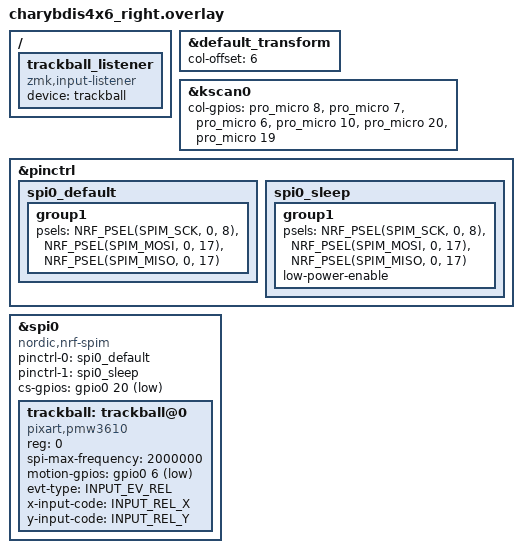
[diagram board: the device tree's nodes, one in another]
#include "charybdis4x6.dtsi"
/* 아래 줄 추가: 마우스 입력 코드를 쓰기 위한 필수 헤더 */
#include <dt-bindings/zmk/input_transform.h>

&default_transform {
    col-offset = <6>;
};

&kscan0 {
    /* 핀맵 유지 */
    col-gpios
        = <&pro_micro 8 (GPIO_ACTIVE_HIGH | GPIO_PULL_DOWN)>
        , <&pro_micro 7 (GPIO_ACTIVE_HIGH | GPIO_PULL_DOWN)>
        , <&pro_micro 6 (GPIO_ACTIVE_HIGH | GPIO_PULL_DOWN)>
        , <&pro_micro 10 (GPIO_ACTIVE_HIGH | GPIO_PULL_DOWN)>
        , <&pro_micro 20 (GPIO_ACTIVE_HIGH | GPIO_PULL_DOWN)>
        , <&pro_micro 19 (GPIO_ACTIVE_HIGH | GPIO_PULL_DOWN)>
        ;
};

&pinctrl {
    spi0_default: spi0_default {
        group1 {
            psels = <NRF_PSEL(SPIM_SCK, 0, 8)>,
                <NRF_PSEL(SPIM_MOSI, 0, 17)>,
                <NRF_PSEL(SPIM_MISO, 0, 17)>;
        };
    };

    spi0_sleep: spi0_sleep {
        group1 {
            psels = <NRF_PSEL(SPIM_SCK, 0, 8)>,
                <NRF_PSEL(SPIM_MOSI, 0, 17)>,
                <NRF_PSEL(SPIM_MISO, 0, 17)>;
            low-power-enable;
        };
    };
};

&spi0 {
    status = "okay";
    compatible = "nordic,nrf-spim";
    pinctrl-0 = <&spi0_default>;
    pinctrl-1 = <&spi0_sleep>;
    pinctrl-names = "default", "sleep";
    cs-gpios = <&gpio0 20 GPIO_ACTIVE_LOW>;

    trackball: trackball@0 {
        status = "okay";
        compatible = "pixart,pmw3610";
        reg = <0>;
        spi-max-frequency = <2000000>;
        
        /* 1. 최신 문법 (IRQ -> Motion) */
        motion-gpios = <&gpio0 6 (GPIO_ACTIVE_LOW | GPIO_PULL_UP)>;

        /* 2. 필수 신분증 추가 (이게 없어서 에러 났음) */
        evt-type = <INPUT_EV_REL>;
        x-input-code = <INPUT_REL_X>;
        y-input-code = <INPUT_REL_Y>;
    };
};

/ {
  trackball_listener {
    compatible = "zmk,input-listener";
    device = <&trackball>;
  };
};
